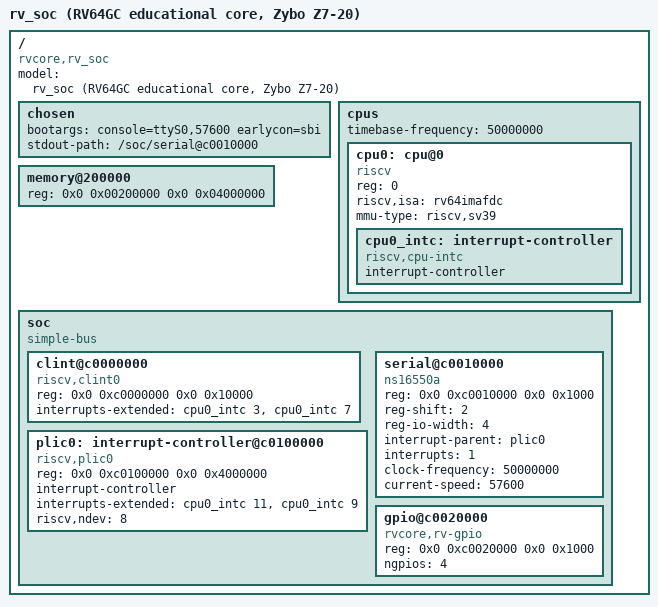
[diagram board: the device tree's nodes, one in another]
/dts-v1/;

/* Real-HARDWARE device tree for the Zybo Z7-20 bitstream (OpenSBI hello payload).
 *
 * Derived from rv_soc_lo.dts (the sim-verified, base-relocated 0x0020_0000 copy).
 * IDENTICAL to rv_soc_lo.dts EXCEPT for the three CLOCK constants below, which on
 * real silicon must reflect the ACTUAL PL clock rather than the sim placeholders.
 * With rv_soc MTIME_DIV=1 the real FCLK_CLK0 = IO PLL (1000 MHz) / divisor, where
 * the divisor is chosen by PCW from build_zybo.tcl PL_FREQMHZ (ps7_init register
 * 0xF8000170); e.g. PL_FREQMHZ=30 realizes 1000/33 = 30.303 MHz, =40 realizes
 * 1000/25 = 40.0 MHz, =50 realizes 1000/20 = 50.0 MHz.
 *
 *   - timebase-frequency = the ACTUAL FCLK in Hz: Linux/OpenSBI convert mtime
 *       deltas to wall time with it; the sim used 1 MHz only because the boot
 *       harness slows mtime via BOOT_MTIME_DIV=64.  Real HW has no such override,
 *       so mtime runs at the real FCLK and the DT must say so, or every delay /
 *       tick period is off (and the HZ tick can re-enter the livelock the sim
 *       avoided with BOOT_MTIME_DIV).
 *   - serial clock-frequency = the ACTUAL FCLK in Hz: the 16550 bit period is
 *       divisor*16 PL clocks and the 8250 driver programs divisor =
 *       clock-frequency/(16*baud); actual_baud = FCLK/(divisor*16), so
 *       clock-frequency MUST equal the real FCLK for the baud to come out right.
 *   - current-speed = console baud (live values + baud error in the inline
 *       comments on each property below).
 *
 * These three constants are rewritten by boards/zybo_z720/set_pl_freq.py <MHz> on
 * a clock retarget -- do NOT hand-edit them out of sync with PL_FREQMHZ.
 *
 * Everything else (memory @ 0x200000 64 MiB == the sim BFM DEPTH, the 0xC0xx
 * peripheral nodes) is base/clock-independent and unchanged from rv_soc_lo.dts.
 * The 64 MiB /memory is kept for bring-up parity with the sim-verified image;
 * expanding to the full 1 GB PS DDR is a later (P2) step.
 */

/ {
    #address-cells = <2>;
    #size-cells = <2>;
    compatible = "rvcore,rv_soc";
    model = "rv_soc (RV64GC educational core, Zybo Z7-20)";

    chosen {
        bootargs = "console=ttyS0,57600 earlycon=sbi";
        stdout-path = "/soc/serial@c0010000";
    };

    cpus {
        #address-cells = <1>;
        #size-cells = <0>;
        timebase-frequency = <50000000>;  /* mtime = PL/MTIME_DIV = 50 MHz/1 */

        cpu0: cpu@0 {
            device_type = "cpu";
            reg = <0>;
            compatible = "riscv";
            riscv,isa = "rv64imafdc";
            mmu-type = "riscv,sv39";
            status = "okay";

            cpu0_intc: interrupt-controller {
                #interrupt-cells = <1>;
                interrupt-controller;
                compatible = "riscv,cpu-intc";
            };
        };
    };

    /* DRAM at the re-linked firmware base (0x0020_0000), 64 MiB for bring-up. */
    memory@200000 {
        device_type = "memory";
        reg = <0x0 0x00200000  0x0 0x04000000>;
    };

    soc {
        #address-cells = <2>;
        #size-cells = <2>;
        compatible = "simple-bus";
        ranges;

        clint@c0000000 {
            compatible = "riscv,clint0";
            reg = <0x0 0xc0000000  0x0 0x10000>;
            interrupts-extended = <&cpu0_intc 3 &cpu0_intc 7>;  /* MSIP, MTIP */
        };

        plic0: interrupt-controller@c0100000 {
            compatible = "riscv,plic0";
            reg = <0x0 0xc0100000  0x0 0x4000000>;
            #interrupt-cells = <1>;
            interrupt-controller;
            interrupts-extended = <&cpu0_intc 11 &cpu0_intc 9>; /* MEIP, SEIP */
            riscv,ndev = <8>;
        };

        serial@c0010000 {
            compatible = "ns16550a";
            reg = <0x0 0xc0010000  0x0 0x1000>;
            reg-shift = <2>;
            reg-io-width = <4>;
            interrupt-parent = <&plic0>;
            interrupts = <1>;
            clock-frequency = <50000000>;  /* = PL clock; sets the 8250 divisor */
            current-speed = <57600>;  /* 50e6/(16*54)=57870, +0.47% */
        };

        gpio@c0020000 {
            compatible = "rvcore,rv-gpio";
            reg = <0x0 0xc0020000  0x0 0x1000>;
            ngpios = <4>;
        };
    };
};
